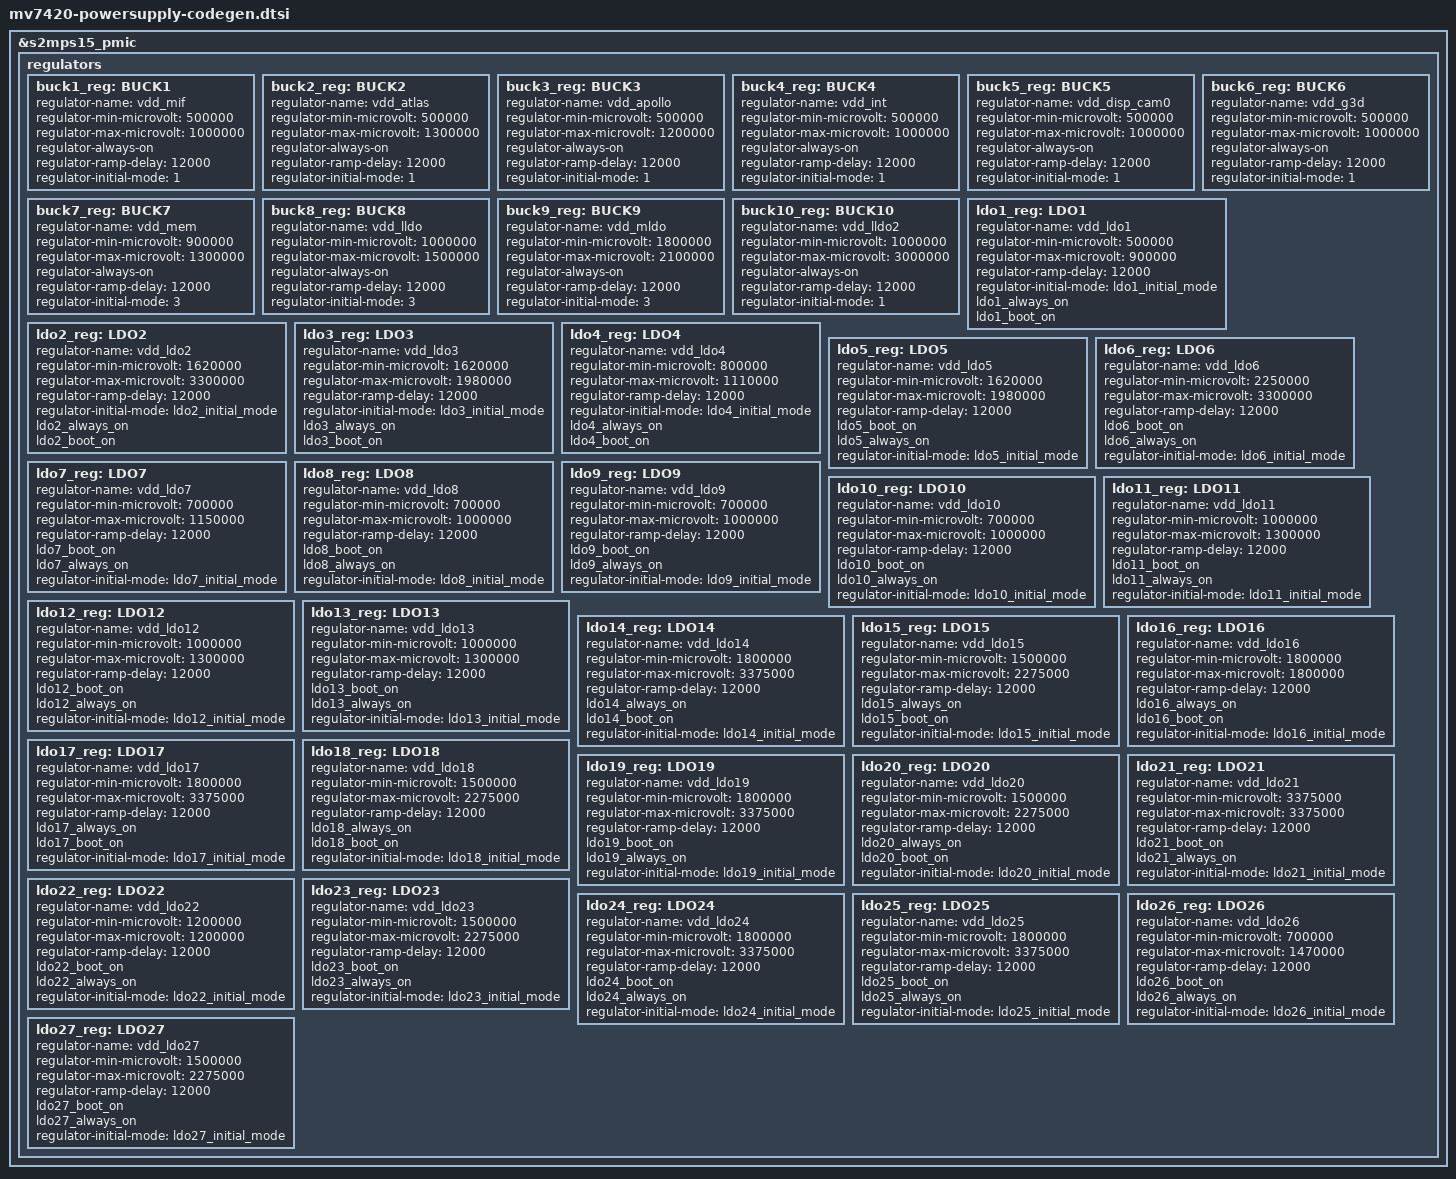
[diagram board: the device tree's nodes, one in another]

#include "exynos7420-pmic-def.h"
#include "mv7420-ldo-codegen.h"

&s2mps15_pmic {
		regulators {
				buck1_reg: BUCK1 {
					regulator-name = "vdd_mif";
					regulator-min-microvolt = <500000>;
					regulator-max-microvolt = <1000000>;
					regulator-always-on;
					regulator-ramp-delay = <12000>;
					regulator-initial-mode = <1>;
				};

				buck2_reg: BUCK2 {
					regulator-name = "vdd_atlas";
					regulator-min-microvolt = <500000>;
					regulator-max-microvolt = <1300000>;
					regulator-always-on;
					regulator-ramp-delay = <12000>;
					regulator-initial-mode = <1>;
				};

				buck3_reg: BUCK3 {
					regulator-name = "vdd_apollo";
					regulator-min-microvolt = <500000>;
					regulator-max-microvolt = <1200000>;
					regulator-always-on;
					regulator-ramp-delay = <12000>;
					regulator-initial-mode = <1>;
				};

				buck4_reg: BUCK4 {
					regulator-name = "vdd_int";
					regulator-min-microvolt = <500000>;
					regulator-max-microvolt = <1000000>;
					regulator-always-on;
					regulator-ramp-delay = <12000>;
					regulator-initial-mode = <1>;
				};

				buck5_reg: BUCK5 {
					regulator-name = "vdd_disp_cam0";
					regulator-min-microvolt = <500000>;
					regulator-max-microvolt = <1000000>;
					regulator-always-on;
					regulator-ramp-delay = <12000>;
					regulator-initial-mode = <1>;
				};

				buck6_reg: BUCK6 {
					regulator-name = "vdd_g3d";
					regulator-min-microvolt = <500000>;
					regulator-max-microvolt = <1000000>;
					regulator-always-on;
					regulator-ramp-delay = <12000>;
					regulator-initial-mode = <1>;
				};

				buck7_reg: BUCK7 {
					regulator-name = "vdd_mem";
					regulator-min-microvolt = <900000>;
					regulator-max-microvolt = <1300000>;
					regulator-always-on;
					regulator-ramp-delay = <12000>;
					regulator-initial-mode = <3>;
				};

				buck8_reg: BUCK8 {
					regulator-name = "vdd_lldo";
					regulator-min-microvolt = <1000000>;
					regulator-max-microvolt = <1500000>;
					regulator-always-on;
					regulator-ramp-delay = <12000>;
					regulator-initial-mode = <3>;
				};

				buck9_reg: BUCK9 {
					regulator-name = "vdd_mldo";
					regulator-min-microvolt = <1800000>;
					regulator-max-microvolt = <2100000>;
					regulator-always-on;
					regulator-ramp-delay = <12000>;
					regulator-initial-mode = <3>;
				};

				buck10_reg: BUCK10 {
					regulator-name = "vdd_lldo2";
					regulator-min-microvolt = <1000000>;
					regulator-max-microvolt = <3000000>;
					regulator-always-on;
					regulator-ramp-delay = <12000>;
					regulator-initial-mode = <1>;
				};

				ldo1_reg: LDO1 {
					regulator-name = "vdd_ldo1";
					regulator-min-microvolt = <500000>;
					regulator-max-microvolt = <900000>;
					regulator-ramp-delay = <12000>;
					regulator-initial-mode = <ldo1_initial_mode>;
					ldo1_always_on;
					ldo1_boot_on;
				};

				ldo2_reg: LDO2 {
					regulator-name = "vdd_ldo2";
					regulator-min-microvolt = <1620000>;
					regulator-max-microvolt = <3300000>;
					regulator-ramp-delay = <12000>;
					regulator-initial-mode = <ldo2_initial_mode>;
					ldo2_always_on;
					ldo2_boot_on;
				};

				ldo3_reg: LDO3 {
					regulator-name = "vdd_ldo3";
					regulator-min-microvolt = <1620000>;
					regulator-max-microvolt = <1980000>;
					regulator-ramp-delay = <12000>;
					regulator-initial-mode = <ldo3_initial_mode>;
					ldo3_always_on;
					ldo3_boot_on;
				};

				ldo4_reg: LDO4 {
					regulator-name = "vdd_ldo4";
					regulator-min-microvolt = <800000>;
					regulator-max-microvolt = <1110000>;
					regulator-ramp-delay = <12000>;
					regulator-initial-mode = <ldo4_initial_mode>;
					ldo4_always_on;
					ldo4_boot_on;
				};

				ldo5_reg: LDO5 {
					regulator-name = "vdd_ldo5";
					regulator-min-microvolt = <1620000>;
					regulator-max-microvolt = <1980000>;
					regulator-ramp-delay = <12000>;
					ldo5_boot_on;
					ldo5_always_on;
					regulator-initial-mode = <ldo5_initial_mode>;
				};

				ldo6_reg: LDO6 {
					regulator-name = "vdd_ldo6";
					regulator-min-microvolt = <2250000>;
					regulator-max-microvolt = <3300000>;
					regulator-ramp-delay = <12000>;
					ldo6_boot_on;
					ldo6_always_on;
					regulator-initial-mode = <ldo6_initial_mode>;
				};

				ldo7_reg: LDO7 {
					regulator-name = "vdd_ldo7";
					regulator-min-microvolt = <700000>;
					regulator-max-microvolt = <1150000>;
					regulator-ramp-delay = <12000>;
					ldo7_boot_on;
					ldo7_always_on;
					regulator-initial-mode = <ldo7_initial_mode>;
				};

				ldo8_reg: LDO8 {
					regulator-name = "vdd_ldo8";
					regulator-min-microvolt = <700000>;
					regulator-max-microvolt = <1000000>;
					regulator-ramp-delay = <12000>;
					ldo8_boot_on;
					ldo8_always_on;
					regulator-initial-mode = <ldo8_initial_mode>;
				};

				ldo9_reg: LDO9 {
					regulator-name = "vdd_ldo9";
					regulator-min-microvolt = <700000>;
					regulator-max-microvolt = <1000000>;
					regulator-ramp-delay = <12000>;
					ldo9_boot_on;
					ldo9_always_on;
					regulator-initial-mode = <ldo9_initial_mode>;
				};

				ldo10_reg: LDO10 {
					regulator-name = "vdd_ldo10";
					regulator-min-microvolt = <700000>;
					regulator-max-microvolt = <1000000>;
					regulator-ramp-delay = <12000>;
					ldo10_boot_on;
					ldo10_always_on;
					regulator-initial-mode = <ldo10_initial_mode>;
				};

				ldo11_reg: LDO11 {
					regulator-name = "vdd_ldo11";
					regulator-min-microvolt = <1000000>;
					regulator-max-microvolt = <1300000>;
					regulator-ramp-delay = <12000>;
					ldo11_boot_on;
					ldo11_always_on;
					regulator-initial-mode = <ldo11_initial_mode>;
				};

				ldo12_reg: LDO12 {
					regulator-name = "vdd_ldo12";
					regulator-min-microvolt = <1000000>;
					regulator-max-microvolt = <1300000>;
					regulator-ramp-delay = <12000>;
					ldo12_boot_on;
					ldo12_always_on;
					regulator-initial-mode = <ldo12_initial_mode>;
				};

				ldo13_reg: LDO13 {
					regulator-name = "vdd_ldo13";
					regulator-min-microvolt = <1000000>;
					regulator-max-microvolt = <1300000>;
					regulator-ramp-delay = <12000>;
					ldo13_boot_on;
					ldo13_always_on;
					regulator-initial-mode = <ldo13_initial_mode>;
				};

				ldo14_reg: LDO14 {
					regulator-name = "vdd_ldo14";
					regulator-min-microvolt = <1800000>;
					regulator-max-microvolt = <3375000>;
					regulator-ramp-delay = <12000>;
					ldo14_always_on;
					ldo14_boot_on;
					regulator-initial-mode = <ldo14_initial_mode>;
				};

				ldo15_reg: LDO15 {
					regulator-name = "vdd_ldo15";
					regulator-min-microvolt = <1500000>;
					regulator-max-microvolt = <2275000>;
					regulator-ramp-delay = <12000>;
					ldo15_always_on;
					ldo15_boot_on;
					regulator-initial-mode = <ldo15_initial_mode>;
				};

				ldo16_reg: LDO16 {
					regulator-name = "vdd_ldo16";
					regulator-min-microvolt = <1800000>;
					regulator-max-microvolt = <1800000>;
					regulator-ramp-delay = <12000>;
					ldo16_always_on;
					ldo16_boot_on;
					regulator-initial-mode = <ldo16_initial_mode>;
				};

				ldo17_reg: LDO17 {
					regulator-name = "vdd_ldo17";
					regulator-min-microvolt = <1800000>;
					regulator-max-microvolt = <3375000>;
					regulator-ramp-delay = <12000>;
					ldo17_always_on;
					ldo17_boot_on;
					regulator-initial-mode = <ldo17_initial_mode>;
				};

				ldo18_reg: LDO18 {
					regulator-name = "vdd_ldo18";
					regulator-min-microvolt = <1500000>;
					regulator-max-microvolt = <2275000>;
					regulator-ramp-delay = <12000>;
					ldo18_always_on;
					ldo18_boot_on;
					regulator-initial-mode = <ldo18_initial_mode>;
				};

				ldo19_reg: LDO19 {
					regulator-name = "vdd_ldo19";
					regulator-min-microvolt = <1800000>;
					regulator-max-microvolt = <3375000>;
					regulator-ramp-delay = <12000>;
					ldo19_boot_on;
					ldo19_always_on;
					regulator-initial-mode = <ldo19_initial_mode>;
				};

				ldo20_reg: LDO20 {
					regulator-name = "vdd_ldo20";
					regulator-min-microvolt = <1500000>;
					regulator-max-microvolt = <2275000>;
					regulator-ramp-delay = <12000>;
					ldo20_always_on;
					ldo20_boot_on;
					regulator-initial-mode = <ldo20_initial_mode>;
				};

				ldo21_reg: LDO21 {
					regulator-name = "vdd_ldo21";
					regulator-min-microvolt = <3375000>;
					regulator-max-microvolt = <3375000>;
					regulator-ramp-delay = <12000>;
					ldo21_boot_on;
					ldo21_always_on;
					regulator-initial-mode = <ldo21_initial_mode>;
				};

				ldo22_reg: LDO22 {
					regulator-name = "vdd_ldo22";
					regulator-min-microvolt = <1200000>;
					regulator-max-microvolt = <1200000>;
					regulator-ramp-delay = <12000>;
					ldo22_boot_on;
					ldo22_always_on;
					regulator-initial-mode = <ldo22_initial_mode>;
				};

				ldo23_reg: LDO23 {
					regulator-name = "vdd_ldo23";
					regulator-min-microvolt = <1500000>;
					regulator-max-microvolt = <2275000>;
					regulator-ramp-delay = <12000>;
					ldo23_boot_on;
					ldo23_always_on;
					regulator-initial-mode = <ldo23_initial_mode>;
				};

				ldo24_reg: LDO24 {
					regulator-name = "vdd_ldo24";
					regulator-min-microvolt = <1800000>;
					regulator-max-microvolt = <3375000>;
					regulator-ramp-delay = <12000>;
					ldo24_boot_on;
					ldo24_always_on;
					regulator-initial-mode = <ldo24_initial_mode>;
				};

				ldo25_reg: LDO25 {
					regulator-name = "vdd_ldo25";
					regulator-min-microvolt = <1800000>;
					regulator-max-microvolt = <3375000>;
					regulator-ramp-delay = <12000>;
					ldo25_boot_on;
					ldo25_always_on;
					regulator-initial-mode = <ldo25_initial_mode>;
				};

				ldo26_reg: LDO26 {
					regulator-name = "vdd_ldo26";
					regulator-min-microvolt = <700000>;
					regulator-max-microvolt = <1470000>;
					regulator-ramp-delay = <12000>;
					ldo26_boot_on;
					ldo26_always_on;
					regulator-initial-mode = <ldo26_initial_mode>;
				};

				ldo27_reg: LDO27 {
					regulator-name = "vdd_ldo27";
					regulator-min-microvolt = <1500000>;
					regulator-max-microvolt = <2275000>;
					regulator-ramp-delay = <12000>;
					ldo27_boot_on;
					ldo27_always_on;
					regulator-initial-mode = <ldo27_initial_mode>;
				};
		};
};
